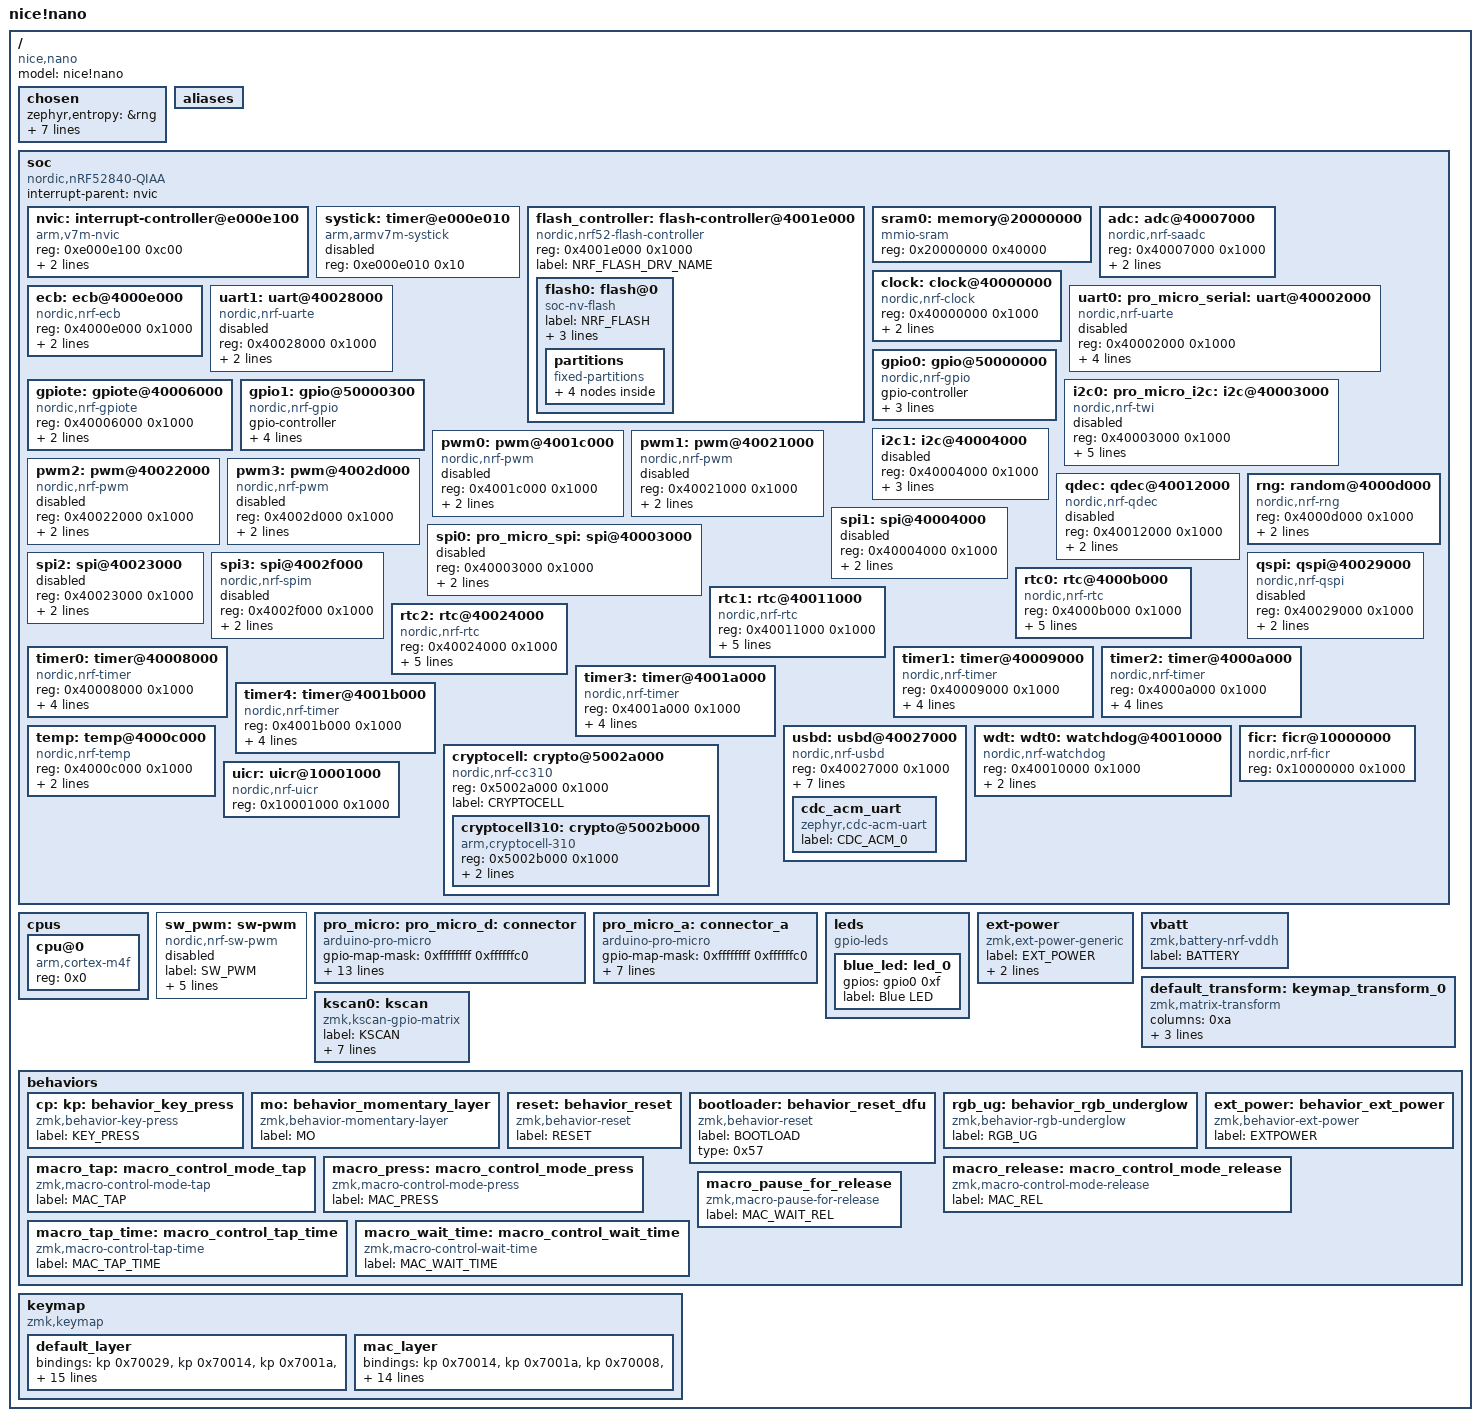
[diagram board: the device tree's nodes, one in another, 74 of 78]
/dts-v1/;

/ {
	#address-cells = < 0x1 >;
	#size-cells = < 0x1 >;
	model = "nice!nano";
	compatible = "nice,nano";
	chosen {
		zephyr,entropy = &rng;
		zephyr,flash-controller = &flash_controller;
		zephyr,code-partition = &code_partition;
		zephyr,sram = &sram0;
		zephyr,flash = &flash0;
		zephyr,console = &cdc_acm_uart;
		zmk,kscan = &kscan0;
		zmk,matrix_transform = &default_transform;
	};
	aliases {
	};
	soc {
		#address-cells = < 0x1 >;
		#size-cells = < 0x1 >;
		compatible = "nordic,nRF52840-QIAA", "nordic,nRF52840", "nordic,nRF52", "simple-bus";
		interrupt-parent = < &nvic >;
		ranges;
		nvic: interrupt-controller@e000e100 {
			compatible = "arm,v7m-nvic";
			reg = < 0xe000e100 0xc00 >;
			interrupt-controller;
			#interrupt-cells = < 0x2 >;
			arm,num-irq-priority-bits = < 0x3 >;
			phandle = < 0x1 >;
		};
		systick: timer@e000e010 {
			compatible = "arm,armv7m-systick";
			reg = < 0xe000e010 0x10 >;
			status = "disabled";
		};
		flash_controller: flash-controller@4001e000 {
			compatible = "nordic,nrf52-flash-controller";
			reg = < 0x4001e000 0x1000 >;
			#address-cells = < 0x1 >;
			#size-cells = < 0x1 >;
			label = "NRF_FLASH_DRV_NAME";
			flash0: flash@0 {
				compatible = "soc-nv-flash";
				label = "NRF_FLASH";
				erase-block-size = < 0x1000 >;
				write-block-size = < 0x4 >;
				reg = < 0x0 0x100000 >;
				partitions {
					compatible = "fixed-partitions";
					#address-cells = < 0x1 >;
					#size-cells = < 0x1 >;
					sd_partition: partition@0 {
						label = "softdevice";
						reg = < 0x0 0x26000 >;
					};
					code_partition: partition@26000 {
						label = "code_partition";
						reg = < 0x26000 0xc6000 >;
					};
					storage_partition: partition@ec000 {
						label = "storage";
						reg = < 0xec000 0x8000 >;
					};
					boot_partition: partition@f4000 {
						label = "adafruit_boot";
						reg = < 0xf4000 0xc000 >;
					};
				};
			};
		};
		sram0: memory@20000000 {
			compatible = "mmio-sram";
			reg = < 0x20000000 0x40000 >;
		};
		adc: adc@40007000 {
			compatible = "nordic,nrf-saadc";
			reg = < 0x40007000 0x1000 >;
			interrupts = < 0x7 0x1 >;
			status = "okay";
			label = "ADC_0";
			#io-channel-cells = < 0x1 >;
		};
		clock: clock@40000000 {
			compatible = "nordic,nrf-clock";
			reg = < 0x40000000 0x1000 >;
			interrupts = < 0x0 0x1 >;
			status = "okay";
			label = "CLOCK";
		};
		ecb: ecb@4000e000 {
			compatible = "nordic,nrf-ecb";
			reg = < 0x4000e000 0x1000 >;
			interrupts = < 0xe 0x1 >;
			status = "okay";
			label = "ECB";
		};
		uart0: pro_micro_serial: uart@40002000 {
			reg = < 0x40002000 0x1000 >;
			interrupts = < 0x2 0x1 >;
			status = "disabled";
			label = "UART_0";
			compatible = "nordic,nrf-uarte";
			tx-pin = < 0x6 >;
			rx-pin = < 0x8 >;
		};
		uart1: uart@40028000 {
			compatible = "nordic,nrf-uarte";
			reg = < 0x40028000 0x1000 >;
			interrupts = < 0x28 0x1 >;
			status = "disabled";
			label = "UART_1";
		};
		gpiote: gpiote@40006000 {
			compatible = "nordic,nrf-gpiote";
			reg = < 0x40006000 0x1000 >;
			interrupts = < 0x6 0x5 >;
			status = "okay";
			label = "GPIOTE_0";
		};
		gpio0: gpio@50000000 {
			compatible = "nordic,nrf-gpio";
			gpio-controller;
			reg = < 0x50000000 0x200 0x50000500 0x300 >;
			#gpio-cells = < 0x2 >;
			label = "GPIO_0";
			status = "okay";
			port = < 0x0 >;
			phandle = < 0x3 >;
		};
		gpio1: gpio@50000300 {
			compatible = "nordic,nrf-gpio";
			gpio-controller;
			reg = < 0x50000300 0x200 0x50000800 0x300 >;
			#gpio-cells = < 0x2 >;
			ngpios = < 0x10 >;
			label = "GPIO_1";
			status = "okay";
			port = < 0x1 >;
			phandle = < 0x4 >;
		};
		i2c0: pro_micro_i2c: i2c@40003000 {
			#address-cells = < 0x1 >;
			#size-cells = < 0x0 >;
			reg = < 0x40003000 0x1000 >;
			clock-frequency = < 0x186a0 >;
			interrupts = < 0x3 0x1 >;
			status = "disabled";
			label = "I2C_0";
			compatible = "nordic,nrf-twi";
			sda-pin = < 0x11 >;
			scl-pin = < 0x14 >;
		};
		i2c1: i2c@40004000 {
			#address-cells = < 0x1 >;
			#size-cells = < 0x0 >;
			reg = < 0x40004000 0x1000 >;
			clock-frequency = < 0x186a0 >;
			interrupts = < 0x4 0x1 >;
			status = "disabled";
			label = "I2C_1";
		};
		pwm0: pwm@4001c000 {
			compatible = "nordic,nrf-pwm";
			reg = < 0x4001c000 0x1000 >;
			interrupts = < 0x1c 0x1 >;
			status = "disabled";
			label = "PWM_0";
			#pwm-cells = < 0x1 >;
		};
		pwm1: pwm@40021000 {
			compatible = "nordic,nrf-pwm";
			reg = < 0x40021000 0x1000 >;
			interrupts = < 0x21 0x1 >;
			status = "disabled";
			label = "PWM_1";
			#pwm-cells = < 0x1 >;
		};
		pwm2: pwm@40022000 {
			compatible = "nordic,nrf-pwm";
			reg = < 0x40022000 0x1000 >;
			interrupts = < 0x22 0x1 >;
			status = "disabled";
			label = "PWM_2";
			#pwm-cells = < 0x1 >;
		};
		pwm3: pwm@4002d000 {
			compatible = "nordic,nrf-pwm";
			reg = < 0x4002d000 0x1000 >;
			interrupts = < 0x2d 0x1 >;
			status = "disabled";
			label = "PWM_3";
			#pwm-cells = < 0x1 >;
		};
		qdec: qdec@40012000 {
			compatible = "nordic,nrf-qdec";
			reg = < 0x40012000 0x1000 >;
			interrupts = < 0x12 0x1 >;
			status = "disabled";
			label = "QDEC";
		};
		rng: random@4000d000 {
			compatible = "nordic,nrf-rng";
			reg = < 0x4000d000 0x1000 >;
			interrupts = < 0xd 0x1 >;
			status = "okay";
			label = "RNG";
		};
		spi0: pro_micro_spi: spi@40003000 {
			#address-cells = < 0x1 >;
			#size-cells = < 0x0 >;
			reg = < 0x40003000 0x1000 >;
			interrupts = < 0x3 0x1 >;
			status = "disabled";
			label = "SPI_0";
		};
		spi1: spi@40004000 {
			#address-cells = < 0x1 >;
			#size-cells = < 0x0 >;
			reg = < 0x40004000 0x1000 >;
			interrupts = < 0x4 0x1 >;
			status = "disabled";
			label = "SPI_1";
		};
		spi2: spi@40023000 {
			#address-cells = < 0x1 >;
			#size-cells = < 0x0 >;
			reg = < 0x40023000 0x1000 >;
			interrupts = < 0x23 0x1 >;
			status = "disabled";
			label = "SPI_2";
		};
		spi3: spi@4002f000 {
			compatible = "nordic,nrf-spim";
			#address-cells = < 0x1 >;
			#size-cells = < 0x0 >;
			reg = < 0x4002f000 0x1000 >;
			interrupts = < 0x2f 0x1 >;
			status = "disabled";
			label = "SPI_3";
		};
		qspi: qspi@40029000 {
			compatible = "nordic,nrf-qspi";
			#address-cells = < 0x1 >;
			#size-cells = < 0x0 >;
			reg = < 0x40029000 0x1000 >;
			interrupts = < 0x29 0x1 >;
			status = "disabled";
			label = "QSPI";
		};
		rtc0: rtc@4000b000 {
			compatible = "nordic,nrf-rtc";
			reg = < 0x4000b000 0x1000 >;
			cc-num = < 0x3 >;
			interrupts = < 0xb 0x1 >;
			status = "okay";
			clock-frequency = < 0x8000 >;
			prescaler = < 0x1 >;
			label = "RTC_0";
		};
		rtc1: rtc@40011000 {
			compatible = "nordic,nrf-rtc";
			reg = < 0x40011000 0x1000 >;
			cc-num = < 0x4 >;
			interrupts = < 0x11 0x1 >;
			status = "okay";
			clock-frequency = < 0x8000 >;
			prescaler = < 0x1 >;
			label = "RTC_1";
		};
		rtc2: rtc@40024000 {
			compatible = "nordic,nrf-rtc";
			reg = < 0x40024000 0x1000 >;
			cc-num = < 0x4 >;
			interrupts = < 0x24 0x1 >;
			status = "okay";
			clock-frequency = < 0x8000 >;
			prescaler = < 0x1 >;
			label = "RTC_2";
		};
		timer0: timer@40008000 {
			compatible = "nordic,nrf-timer";
			status = "okay";
			reg = < 0x40008000 0x1000 >;
			cc-num = < 0x4 >;
			interrupts = < 0x8 0x1 >;
			prescaler = < 0x0 >;
			label = "TIMER_0";
		};
		timer1: timer@40009000 {
			compatible = "nordic,nrf-timer";
			status = "okay";
			reg = < 0x40009000 0x1000 >;
			cc-num = < 0x4 >;
			interrupts = < 0x9 0x1 >;
			prescaler = < 0x0 >;
			label = "TIMER_1";
		};
		timer2: timer@4000a000 {
			compatible = "nordic,nrf-timer";
			status = "okay";
			reg = < 0x4000a000 0x1000 >;
			cc-num = < 0x4 >;
			interrupts = < 0xa 0x1 >;
			prescaler = < 0x0 >;
			label = "TIMER_2";
			phandle = < 0x2 >;
		};
		timer3: timer@4001a000 {
			compatible = "nordic,nrf-timer";
			status = "okay";
			reg = < 0x4001a000 0x1000 >;
			cc-num = < 0x6 >;
			interrupts = < 0x1a 0x1 >;
			prescaler = < 0x0 >;
			label = "TIMER_3";
		};
		timer4: timer@4001b000 {
			compatible = "nordic,nrf-timer";
			status = "okay";
			reg = < 0x4001b000 0x1000 >;
			cc-num = < 0x6 >;
			interrupts = < 0x1b 0x1 >;
			prescaler = < 0x0 >;
			label = "TIMER_4";
		};
		temp: temp@4000c000 {
			compatible = "nordic,nrf-temp";
			reg = < 0x4000c000 0x1000 >;
			interrupts = < 0xc 0x1 >;
			status = "okay";
			label = "TEMP_0";
		};
		usbd: usbd@40027000 {
			compatible = "nordic,nrf-usbd";
			reg = < 0x40027000 0x1000 >;
			interrupts = < 0x27 0x1 >;
			num-bidir-endpoints = < 0x1 >;
			num-in-endpoints = < 0x7 >;
			num-out-endpoints = < 0x7 >;
			num-isoin-endpoints = < 0x1 >;
			num-isoout-endpoints = < 0x1 >;
			status = "okay";
			label = "USBD";
			cdc_acm_uart: cdc_acm_uart {
				compatible = "zephyr,cdc-acm-uart";
				label = "CDC_ACM_0";
			};
		};
		wdt: wdt0: watchdog@40010000 {
			compatible = "nordic,nrf-watchdog";
			reg = < 0x40010000 0x1000 >;
			interrupts = < 0x10 0x1 >;
			status = "okay";
			label = "WDT";
		};
		cryptocell: crypto@5002a000 {
			compatible = "nordic,nrf-cc310";
			reg = < 0x5002a000 0x1000 >;
			label = "CRYPTOCELL";
			status = "okay";
			#address-cells = < 0x1 >;
			#size-cells = < 0x1 >;
			cryptocell310: crypto@5002b000 {
				compatible = "arm,cryptocell-310";
				reg = < 0x5002b000 0x1000 >;
				interrupts = < 0x2a 0x1 >;
				label = "CRYPTOCELL310";
			};
		};
		ficr: ficr@10000000 {
			compatible = "nordic,nrf-ficr";
			reg = < 0x10000000 0x1000 >;
			status = "okay";
		};
		uicr: uicr@10001000 {
			compatible = "nordic,nrf-uicr";
			reg = < 0x10001000 0x1000 >;
			status = "okay";
		};
	};
	cpus {
		#address-cells = < 0x1 >;
		#size-cells = < 0x0 >;
		cpu@0 {
			device_type = "cpu";
			compatible = "arm,cortex-m4f";
			reg = < 0x0 >;
		};
	};
	sw_pwm: sw-pwm {
		compatible = "nordic,nrf-sw-pwm";
		status = "disabled";
		label = "SW_PWM";
		generator = < &timer2 >;
		channel-count = < 0x3 >;
		clock-prescaler = < 0x0 >;
		ppi-base = < 0x0 >;
		gpiote-base = < 0x0 >;
		#pwm-cells = < 0x1 >;
	};
	pro_micro: pro_micro_d: connector {
		compatible = "arduino-pro-micro";
		#gpio-cells = < 0x2 >;
		gpio-map-mask = < 0xffffffff 0xffffffc0 >;
		gpio-map-pass-thru = < 0x0 0x3f >;
		gpio-map = < 0x0 0x0 &gpio0 0x8 0x0 >, < 0x1 0x0 &gpio0 0x6 0x0 >, < 0x2 0x0 &gpio0 0x11 0x0 >, < 0x3 0x0 &gpio0 0x14 0x0 >, < 0x4 0x0 &gpio0 0x16 0x0 >, < 0x5 0x0 &gpio0 0x18 0x0 >, < 0x6 0x0 &gpio1 0x0 0x0 >, < 0x7 0x0 &gpio0 0xb 0x0 >, < 0x8 0x0 &gpio1 0x4 0x0 >, < 0x9 0x0 &gpio1 0x6 0x0 >, < 0xa 0x0 &gpio0 0x9 0x0 >, < 0x10 0x0 &gpio0 0xa 0x0 >, < 0xe 0x0 &gpio1 0xb 0x0 >, < 0xf 0x0 &gpio1 0xd 0x0 >, < 0x12 0x0 &gpio1 0xf 0x0 >, < 0x13 0x0 &gpio0 0x2 0x0 >, < 0x14 0x0 &gpio0 0x1d 0x0 >, < 0x15 0x0 &gpio0 0x1f 0x0 >;
	};
	pro_micro_a: connector_a {
		compatible = "arduino-pro-micro";
		#gpio-cells = < 0x2 >;
		gpio-map-mask = < 0xffffffff 0xffffffc0 >;
		gpio-map-pass-thru = < 0x0 0x3f >;
		gpio-map = < 0x0 0x0 &gpio1 0xf 0x0 >, < 0x1 0x0 &gpio0 0x2 0x0 >, < 0x2 0x0 &gpio0 0x1d 0x0 >, < 0x3 0x0 &gpio0 0x1f 0x0 >, < 0x6 0x0 &gpio0 0x16 0x0 >, < 0x7 0x0 &gpio1 0x0 0x0 >, < 0x8 0x0 &gpio1 0x4 0x0 >, < 0x9 0x0 &gpio1 0x6 0x0 >, < 0xa 0x0 &gpio0 0x9 0x0 >;
	};
	leds {
		compatible = "gpio-leds";
		blue_led: led_0 {
			gpios = < &gpio0 0xf 0x0 >;
			label = "Blue LED";
		};
	};
	ext-power {
		compatible = "zmk,ext-power-generic";
		label = "EXT_POWER";
		control-gpios = < &gpio0 0xd 0x0 >;
		init-delay-ms = < 0x32 >;
	};
	vbatt {
		compatible = "zmk,battery-nrf-vddh";
		label = "BATTERY";
	};
	default_transform: keymap_transform_0 {
		compatible = "zmk,matrix-transform";
		columns = < 0xa >;
		rows = < 0x5 >;
		map = < 0x0 0x1 0x2 0x3 0x4 0x5 0x6 0x7 0x8 0x9 0xa 0xb 0x100 0x101 0x102 0x103 0x104 0x105 0x106 0x107 0x108 0x109 0x10a 0x10b 0x200 0x201 0x202 0x203 0x204 0x205 0x206 0x207 0x208 0x209 0x20a 0x20b 0x301 0x302 0x307 0x308 0x402 0x303 0x304 0x305 0x306 0x407 0x403 0x404 0x405 0x406 0x504 0x505 >;
	};
	kscan0: kscan {
		compatible = "zmk,kscan-gpio-matrix";
		label = "KSCAN";
		diode-direction = "col2row";
		row-gpios = < &gpio0 0x9 0x20 >, < &gpio0 0xa 0x20 >, < &gpio1 0xb 0x20 >, < &gpio1 0xd 0x20 >, < &gpio1 0xf 0x20 >, < &gpio0 0x2 0x20 >;
		col-gpios = < &gpio0 0x16 0x0 >, < &gpio0 0x18 0x0 >, < &gpio1 0x0 0x0 >, < &gpio0 0xb 0x0 >, < &gpio1 0x4 0x0 >, < &gpio1 0x6 0x0 >;
		debounce-press-ms = < 0x1e >;
		debounce-release-ms = < 0x1e >;
	};
	behaviors {
		cp: kp: behavior_key_press {
			compatible = "zmk,behavior-key-press";
			label = "KEY_PRESS";
			#binding-cells = < 0x1 >;
			phandle = < 0x5 >;
		};
		mo: behavior_momentary_layer {
			compatible = "zmk,behavior-momentary-layer";
			label = "MO";
			#binding-cells = < 0x1 >;
			phandle = < 0x6 >;
		};
		reset: behavior_reset {
			compatible = "zmk,behavior-reset";
			label = "RESET";
			#binding-cells = < 0x0 >;
		};
		bootloader: behavior_reset_dfu {
			compatible = "zmk,behavior-reset";
			label = "BOOTLOAD";
			type = < 0x57 >;
			#binding-cells = < 0x0 >;
		};
		rgb_ug: behavior_rgb_underglow {
			compatible = "zmk,behavior-rgb-underglow";
			label = "RGB_UG";
			#binding-cells = < 0x2 >;
		};
		ext_power: behavior_ext_power {
			compatible = "zmk,behavior-ext-power";
			label = "EXTPOWER";
			#binding-cells = < 0x1 >;
		};
		macro_tap: macro_control_mode_tap {
			compatible = "zmk,macro-control-mode-tap";
			label = "MAC_TAP";
			#binding-cells = < 0x0 >;
		};
		macro_press: macro_control_mode_press {
			compatible = "zmk,macro-control-mode-press";
			label = "MAC_PRESS";
			#binding-cells = < 0x0 >;
		};
		macro_release: macro_control_mode_release {
			compatible = "zmk,macro-control-mode-release";
			label = "MAC_REL";
			#binding-cells = < 0x0 >;
		};
		macro_tap_time: macro_control_tap_time {
			compatible = "zmk,macro-control-tap-time";
			label = "MAC_TAP_TIME";
			#binding-cells = < 0x1 >;
		};
		macro_wait_time: macro_control_wait_time {
			compatible = "zmk,macro-control-wait-time";
			label = "MAC_WAIT_TIME";
			#binding-cells = < 0x1 >;
		};
		macro_pause_for_release: macro_pause_for_release {
			compatible = "zmk,macro-pause-for-release";
			label = "MAC_WAIT_REL";
			#binding-cells = < 0x0 >;
		};
	};
	keymap {
		compatible = "zmk,keymap";
		default_layer {
			bindings = < &kp 0x70029 &kp 0x70014 &kp 0x7001a &kp 0x70008 &kp 0x70015 &kp 0x70017 &kp 0x7001c &kp 0x70018 &kp 0x7000c &kp 0x70012 &kp 0x70013 &kp 0x7002b &kp 0x70004 &kp 0x70016 &kp 0x70007 &kp 0x70009 &kp 0x7000a &kp 0x7000b &kp 0x7000d &kp 0x7000e &kp 0x7000f &kp 0x70033 &kp 0x700e5 &kp 0x7001d &kp 0x7001b &kp 0x70006 &kp 0x70019 &kp 0x70005 &kp 0x70011 &kp 0x70010 &kp 0x70036 &kp 0x70037 &kp 0x70038 &kp 0x70050 &kp 0x7004f &kp 0x70051 &kp 0x70052 &kp 0x7002a &kp 0x70029 &kp 0x7004c &kp 0x70028 &kp 0x7002c &kp 0x70035 &kp 0x7002a &kp 0x700e0 &kp 0x700e2 >;
		};
		mac_layer {
			bindings = < &kp 0x70014 &kp 0x7001a &kp 0x70008 &kp 0x70015 &kp 0x70017 &kp 0x7001c &kp 0x70018 &kp 0x7000c &kp 0x70012 &kp 0x70013 &kp 0x70004 &kp 0x70016 &kp 0x70007 &kp 0x70009 &kp 0x7000a &kp 0x7000b &kp 0x7000d &kp 0x7000e &kp 0x7000f &kp 0x70033 &kp 0x7001d &kp 0x7001b &kp 0x70006 &kp 0x70019 &kp 0x70005 &kp 0x70011 &kp 0x70010 &kp 0x70036 &kp 0x70037 &kp 0x70038 &kp 0x70050 &kp 0x7004f &kp 0x70051 &kp 0x70052 &kp 0x7002a &kp 0x70029 &kp 0x7004c &kp 0x70028 &kp 0x7002c &kp 0x70035 &kp 0x7002a &kp 0x700e0 &kp 0x700e2 >;
		};
	};
};
